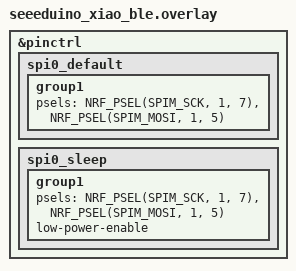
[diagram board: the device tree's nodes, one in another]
 &pinctrl {
    spi0_default: spi0_default {
        /* node name is arbitrary */
        group1 {
            psels = <NRF_PSEL(SPIM_SCK, 1, 7)>,
                    <NRF_PSEL(SPIM_MOSI, 1, 5)>;

        };
    };

    spi0_sleep: spi0_sleep {
        group1 {
            psels = <NRF_PSEL(SPIM_SCK, 1, 7)>,
                    <NRF_PSEL(SPIM_MOSI, 1, 5)>;
            low-power-enable;
        };
    };

};
